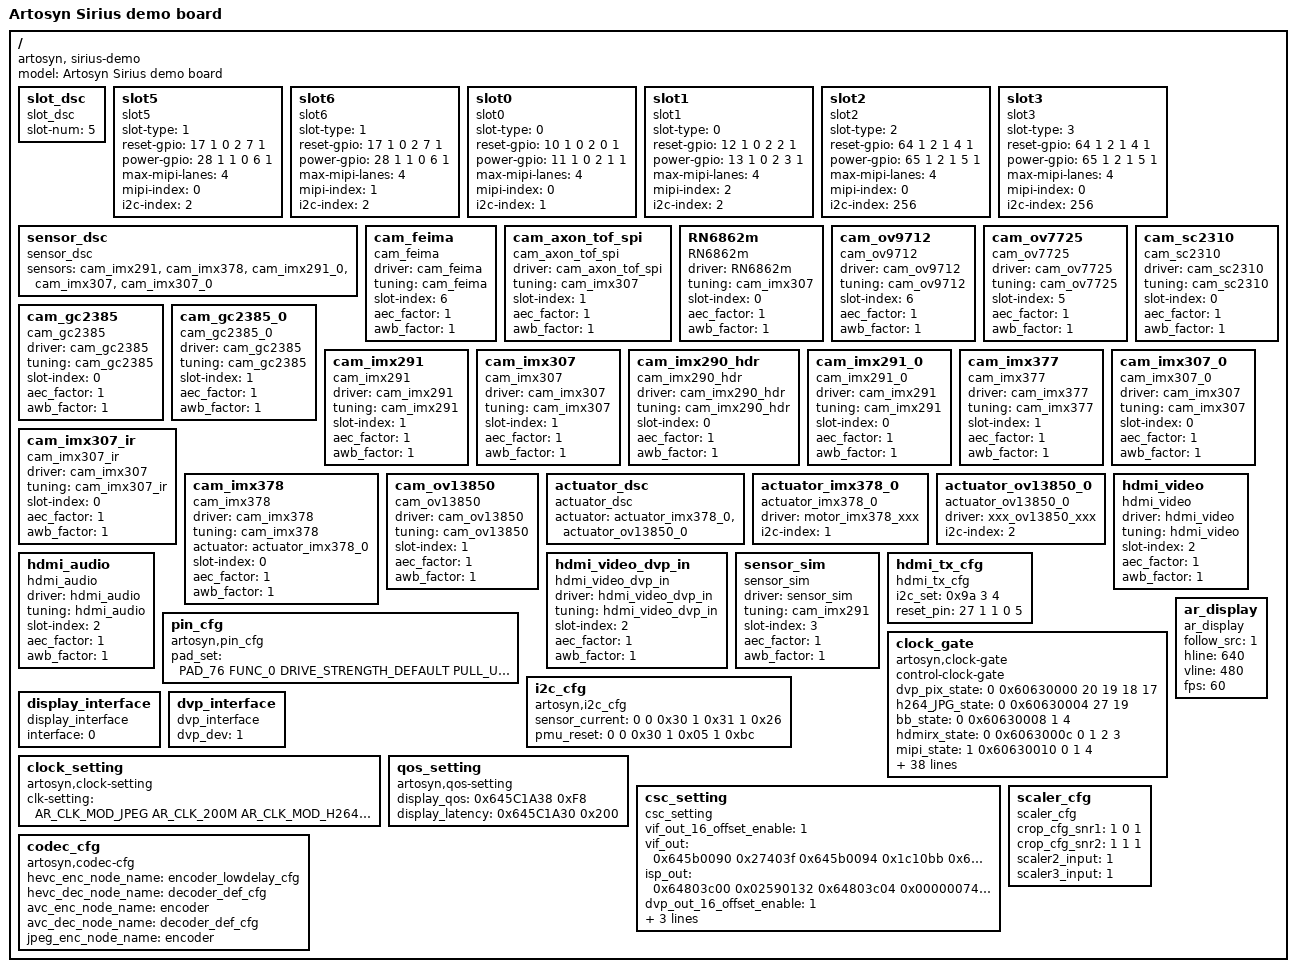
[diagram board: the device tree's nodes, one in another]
/*
 * Copyright 2015 Hans de Goede <hdegoede@redhat.com>
 *
 * Minimal dts file for the MSI Primo81 for u-boot only
 *
 * SPDX-License-Identifier:     GPL-2.0+ or X11
 */


/dts-v1/;
#include <ar_clk.h>
#include <ar_pads.h>

/{
	model = "Artosyn Sirius demo board";
	compatible = "artosyn, sirius-demo";

	slot_dsc{
		compatible = "slot_dsc";
		slot-num = <5>;
	};

	slot5 {
		compatible = "slot5";
		slot-type = <1>;
		//padnum, gpio_function_num ,group, port,num,in_out
		reset-gpio = <17 1 0 2 7 1>;
        //dvp power not config
		power-gpio = <28 1 1 0 6 1>;
		//mipi lane num
		max-mipi-lanes = <4>;
        //dvp_index
		mipi-index = <0>;
		//i2c index
		i2c-index = <2>;

	};

	slot6 {
		compatible = "slot6";
		slot-type = <1>;
		//padnum, gpio_function_num ,group, port,num,in_out
		reset-gpio = <17 1 0 2 7 1>;
        //dvp power not config
		power-gpio = <28 1 1 0 6 1>;
		//mipi lane num
		max-mipi-lanes = <4>;
        //dvp_index
		mipi-index = <1>;
		//i2c index
		i2c-index = <2>;

	};
	slot0 {
		compatible = "slot0";
		slot-type = <0>;
		//padnum, gpio_function_num ,group, port,num,in_out
		reset-gpio = <10 1 0 2 0 1>;
		power-gpio = <11 1 0 2 1 1>;
		//mipi lane num
		max-mipi-lanes = <4>;
		mipi-index = <0>;
		//i2c index
		i2c-index = <1>;

	};

	slot1 {
		compatible = "slot1";
		slot-type = <0>;
		//padnum, gpio_function_num ,group, port,num,in_out
		reset-gpio = <12 1 0 2 2 1>;
		power-gpio = <13 1 0 2 3 1>;
		//mipi lane num
		max-mipi-lanes = <4>;
		mipi-index = <2>;
		//i2c index
		i2c-index = <2>;

	};
	slot2 {
		compatible = "slot2";
		slot-type = <2>;
		//padnum, gpio_function_num ,group, port,num,in_out
		reset-gpio = <64 1 2 1 4 1>;
		power-gpio = <65 1 2 1 5 1>;
		//mipi lane num
		max-mipi-lanes = <4>;
		mipi-index = <0>;
		//i2c index
		i2c-index = <256>;

	};
	slot3 {
		compatible = "slot3";
		slot-type = <3>;
		//padnum, gpio_function_num ,group, port,num,in_out
		reset-gpio = <64 1 2 1 4 1>;
		power-gpio = <65 1 2 1 5 1>;
		//mipi lane num
		max-mipi-lanes = <4>;
		mipi-index = <0>;
		//i2c index
		i2c-index = <256>;

	};
	sensor_dsc{
		compatible = "sensor_dsc";
                //the sensor need to prob
		sensors ="cam_imx291" , "cam_imx378", "cam_imx291_0" , "cam_imx307" , "cam_imx307_0";
	};
        //comatible will decidecd which driver will used
        //node will give the driver to creat sensor obj which name is it, and this name will decided which tuning header will
        //be used
    cam_feima{
        compatible = "cam_feima";
        driver       = "cam_feima";
        tuning      = "cam_feima";
        slot-index = <6>;
        aec_factor = <1>;
        awb_factor = <1>;
    };
    cam_axon_tof_spi{
        compatible   = "cam_axon_tof_spi";
        driver       = "cam_axon_tof_spi";
        tuning       = "cam_imx307";
        slot-index   = <1>;
        aec_factor   = <1>;
        awb_factor   = <1>;
    };
    RN6862m{
        compatible = "RN6862m";
        driver       = "RN6862m";
        tuning      = "cam_imx307";
        slot-index = <0>;
        aec_factor = <1>;
        awb_factor = <1>;
    };
    cam_ov9712{
        compatible = "cam_ov9712";
        driver       = "cam_ov9712";
        tuning      = "cam_ov9712";
        slot-index = <6>;
        aec_factor = <1>;
        awb_factor = <1>;
    };
    cam_ov7725{
        compatible = "cam_ov7725";
        driver       = "cam_ov7725";
        tuning      = "cam_ov7725";
        slot-index = <5>;
        aec_factor = <1>;
        awb_factor = <1>;
    };
	cam_sc2310{
		compatible = "cam_sc2310";
                driver       = "cam_sc2310";
                tuning      = "cam_sc2310";
		slot-index = <0>;
		aec_factor = <1>;
		awb_factor = <1>;
	};
	cam_gc2385{
		compatible = "cam_gc2385";
                driver       = "cam_gc2385";
                tuning       = "cam_gc2385";
		slot-index = <0>;
		aec_factor = <1>;
		awb_factor = <1>;
	};

	cam_gc2385_0{
		compatible = "cam_gc2385_0";
                driver       = "cam_gc2385";
                tuning       = "cam_gc2385";
		slot-index = <1>;
		aec_factor = <1>;
		awb_factor = <1>;
	};
	cam_imx291{
		compatible = "cam_imx291";
                driver       = "cam_imx291";
                tuning       = "cam_imx291";
		slot-index = <1>;
		aec_factor = <1>;
		awb_factor = <1>;
	};
	cam_imx307{
		compatible = "cam_imx307";
                driver = "cam_imx307";
                tuning= "cam_imx307";
		slot-index = <1>;
		aec_factor = <1>;
		awb_factor = <1>;
	};
        cam_imx290_hdr{
		compatible = "cam_imx290_hdr";
                driver = "cam_imx290_hdr";
                tuning = "cam_imx290_hdr";
		slot-index = <0>;
		aec_factor = <1>;
		awb_factor = <1>;
	};
	cam_imx291_0{
		compatible = "cam_imx291_0";
                driver = "cam_imx291";
                tuning = "cam_imx291";
		slot-index = <0>;
		aec_factor = <1>;
		awb_factor = <1>;
		};
	cam_imx377{
		compatible = "cam_imx377";
                driver      = "cam_imx377";
                tuning     = "cam_imx377";
		slot-index = <1>;
		aec_factor = <1>;
		awb_factor = <1>;
	};

	cam_imx307_0{
		compatible = "cam_imx307_0";
                driver = "cam_imx307";
                tuning= "cam_imx307";
		slot-index = <0>;
		aec_factor = <1>;
		awb_factor = <1>;
	};

	cam_imx307_ir{
		compatible = "cam_imx307_ir";
                driver = "cam_imx307";
                tuning= "cam_imx307_ir";
		slot-index = <0>;
		aec_factor = <1>;
		awb_factor = <1>;
	};
    cam_imx378{
        compatible   = "cam_imx378";
        driver       = "cam_imx378";
        tuning       = "cam_imx378";
        actuator     = "actuator_imx378_0";
        slot-index   = <0>;
        aec_factor   = <1>;
        awb_factor   = <1>;
    };

	cam_ov13850{
		compatible = "cam_ov13850";
                driver     = "cam_ov13850";
                tuning     = "cam_ov13850";
		slot-index = <1>;
		aec_factor = <1>;
		awb_factor = <1>;
	};

    actuator_dsc{
        compatible = "actuator_dsc";
        //the actuator need to be created max 16
        actuator = "actuator_imx378_0" , "actuator_ov13850_0";
    };
    actuator_imx378_0{
        compatible = "actuator_imx378_0";
        driver = "motor_imx378_xxx";
        i2c-index = <1>;
    };
    actuator_ov13850_0{
        compatible = "actuator_ov13850_0";
        driver = "xxx_ov13850_xxx";
        i2c-index = <2>;
    };

	hdmi_video{
		compatible = "hdmi_video";
                driver       = "hdmi_video";
                tuning      = "hdmi_video";
		slot-index = <2>;
		aec_factor = <1>;
		awb_factor = <1>;
	};
	hdmi_audio{
		compatible = "hdmi_audio";
                driver       = "hdmi_audio";
                tuning     = "hdmi_audio";
		slot-index = <2>;
		aec_factor = <1>;
		awb_factor = <1>;
	};
	hdmi_video_dvp_in{
		compatible = "hdmi_video_dvp_in";
                driver       =  "hdmi_video_dvp_in";
                tuning    = "hdmi_video_dvp_in";
		slot-index = <2>;
		aec_factor = <1>;
		awb_factor = <1>;
	};
       sensor_sim{
		compatible = "sensor_sim";
                driver = "sensor_sim";
                tuning = "cam_imx291";
		slot-index = <3>;
		aec_factor = <1>;
		awb_factor = <1>;
	};

	hdmi_tx_cfg {
		compatible = "hdmi_tx_cfg";
		//<i2c_component subaddr>
		i2c_set = <0x9a 3 4>;
		//<pad function group port gpio>
		reset_pin = <27 1 1 0 5>;
	};

	pin_cfg {
                compatible = "artosyn,pin_cfg";
                pad_set  =    <
				//pin_share_qspi
				PAD_76	FUNC_0	DRIVE_STRENGTH_DEFAULT	PULL_UP_OR_DOWN_DEFAULT	VALUE_DEFAULT
				PAD_77	FUNC_0	DRIVE_STRENGTH_DEFAULT	PULL_UP_OR_DOWN_DEFAULT	VALUE_DEFAULT
				PAD_78	FUNC_0	DRIVE_STRENGTH_DEFAULT	PULL_UP_OR_DOWN_DEFAULT	VALUE_DEFAULT
				PAD_79	FUNC_0	DRIVE_STRENGTH_DEFAULT	PULL_UP_OR_DOWN_DEFAULT	VALUE_DEFAULT
				PAD_80	FUNC_0	DRIVE_STRENGTH_DEFAULT	PULL_UP_OR_DOWN_DEFAULT	VALUE_DEFAULT
				PAD_81	FUNC_0	DRIVE_STRENGTH_DEFAULT	PULL_UP_OR_DOWN_DEFAULT	VALUE_DEFAULT
				PAD_82	FUNC_0	DRIVE_STRENGTH_DEFAULT	PULL_UP_OR_DOWN_DEFAULT	VALUE_DEFAULT
				PAD_83	FUNC_0	DRIVE_STRENGTH_DEFAULT	PULL_UP_OR_DOWN_DEFAULT	VALUE_DEFAULT
				//pin_share_ethnet
				PAD_121	FUNC_0	DRIVE_STRENGTH_DEFAULT	PULL_UP_OR_DOWN_DEFAULT	VALUE_DEFAULT
				PAD_122	FUNC_0	DRIVE_STRENGTH_DEFAULT	PULL_UP_OR_DOWN_DEFAULT	VALUE_DEFAULT
				PAD_123	FUNC_0	DRIVE_STRENGTH_DEFAULT	PULL_UP_OR_DOWN_DEFAULT	VALUE_DEFAULT
				PAD_124	FUNC_0	DRIVE_STRENGTH_DEFAULT	PULL_UP_OR_DOWN_DEFAULT	VALUE_DEFAULT
				PAD_125	FUNC_0	DRIVE_STRENGTH_DEFAULT	PULL_UP_OR_DOWN_DEFAULT	VALUE_DEFAULT
				PAD_126	FUNC_0	DRIVE_STRENGTH_DEFAULT	PULL_UP_OR_DOWN_DEFAULT	VALUE_DEFAULT
				PAD_127	FUNC_0	DRIVE_STRENGTH_DEFAULT	PULL_UP_OR_DOWN_DEFAULT	VALUE_DEFAULT
				PAD_128	FUNC_0	DRIVE_STRENGTH_DEFAULT	PULL_UP_OR_DOWN_DEFAULT	VALUE_DEFAULT
				PAD_129	FUNC_0	DRIVE_STRENGTH_DEFAULT	PULL_UP_OR_DOWN_DEFAULT	VALUE_DEFAULT
				PAD_130	FUNC_0	DRIVE_STRENGTH_DEFAULT	PULL_UP_OR_DOWN_DEFAULT	VALUE_DEFAULT
				PAD_131	FUNC_0	DRIVE_STRENGTH_DEFAULT	PULL_UP_OR_DOWN_DEFAULT	VALUE_DEFAULT
				PAD_132	FUNC_0	DRIVE_STRENGTH_DEFAULT	PULL_UP_OR_DOWN_DEFAULT	VALUE_DEFAULT
				PAD_133	FUNC_0	DRIVE_STRENGTH_DEFAULT	PULL_UP_OR_DOWN_DEFAULT	VALUE_DEFAULT
				PAD_134	FUNC_0	DRIVE_STRENGTH_DEFAULT	PULL_UP_OR_DOWN_DEFAULT	VALUE_DEFAULT
				PAD_135	FUNC_0	DRIVE_STRENGTH_DEFAULT	PULL_UP_OR_DOWN_DEFAULT	VALUE_DEFAULT
				PAD_136	FUNC_0	DRIVE_STRENGTH_DEFAULT	PULL_UP_OR_DOWN_DEFAULT	VALUE_DEFAULT
				PAD_137	FUNC_0	DRIVE_STRENGTH_DEFAULT	PULL_UP_OR_DOWN_DEFAULT	VALUE_DEFAULT
				//pin_share_i2s_master1_for_sensor_clock
				PAD_64	FUNC_0	DRIVE_STRENGTH_DEFAULT	PULL_UP_OR_DOWN_DEFAULT	VALUE_DEFAULT
				PAD_65	FUNC_0	DRIVE_STRENGTH_DEFAULT	PULL_UP_OR_DOWN_DEFAULT	VALUE_DEFAULT
				PAD_66	FUNC_0	DRIVE_STRENGTH_DEFAULT	PULL_UP_OR_DOWN_DEFAULT	VALUE_DEFAULT
				PAD_67	FUNC_0	DRIVE_STRENGTH_DEFAULT	PULL_UP_OR_DOWN_DEFAULT	VALUE_DEFAULT
				//pin_share_bb_spi
				PAD_6	FUNC_4	DRIVE_STRENGTH_DEFAULT	PULL_UP_OR_DOWN_DEFAULT	VALUE_DEFAULT
				PAD_7	FUNC_4	DRIVE_STRENGTH_DEFAULT	PULL_UP_OR_DOWN_DEFAULT	VALUE_DEFAULT
				PAD_8	FUNC_4	DRIVE_STRENGTH_DEFAULT	PULL_UP_OR_DOWN_DEFAULT	VALUE_DEFAULT
				PAD_9	FUNC_4	DRIVE_STRENGTH_DEFAULT	PULL_UP_OR_DOWN_DEFAULT	VALUE_DEFAULT
				PAD_18	FUNC_2	DRIVE_STRENGTH_DEFAULT	PULL_UP_OR_DOWN_DEFAULT	VALUE_DEFAULT
				PAD_19	FUNC_2	DRIVE_STRENGTH_DEFAULT	PULL_UP_OR_DOWN_DEFAULT	VALUE_DEFAULT
				PAD_20	FUNC_2	DRIVE_STRENGTH_DEFAULT	PULL_UP_OR_DOWN_DEFAULT	VALUE_DEFAULT
				PAD_21	FUNC_2	DRIVE_STRENGTH_DEFAULT	PULL_UP_OR_DOWN_DEFAULT	VALUE_DEFAULT
				PAD_26	FUNC_0	DRIVE_STRENGTH_DEFAULT	PULL_UP_OR_DOWN_DEFAULT	VALUE_DEFAULT
				PAD_27	FUNC_1	DRIVE_STRENGTH_DEFAULT	PULL_UP_OR_DOWN_DEFAULT	VALUE_DEFAULT
				PAD_28	FUNC_0	DRIVE_STRENGTH_DEFAULT	PULL_UP_OR_DOWN_DEFAULT	VALUE_DEFAULT
				PAD_29	FUNC_0	DRIVE_STRENGTH_DEFAULT	PULL_UP_OR_DOWN_DEFAULT	VALUE_DEFAULT
				PAD_68	FUNC_4	DRIVE_STRENGTH_DEFAULT	PULL_UP_OR_DOWN_DEFAULT	VALUE_DEFAULT
				PAD_69	FUNC_4	DRIVE_STRENGTH_DEFAULT	PULL_UP_OR_DOWN_DEFAULT	VALUE_DEFAULT
				PAD_70	FUNC_4	DRIVE_STRENGTH_DEFAULT	PULL_UP_OR_DOWN_DEFAULT	VALUE_DEFAULT
				PAD_71	FUNC_4	DRIVE_STRENGTH_DEFAULT	PULL_UP_OR_DOWN_DEFAULT	VALUE_DEFAULT
				PAD_72	FUNC_4	DRIVE_STRENGTH_DEFAULT	PULL_UP_OR_DOWN_DEFAULT	VALUE_DEFAULT
				PAD_73	FUNC_4	DRIVE_STRENGTH_DEFAULT	PULL_UP_OR_DOWN_DEFAULT	VALUE_DEFAULT
				PAD_74	FUNC_4	DRIVE_STRENGTH_DEFAULT	PULL_UP_OR_DOWN_DEFAULT	VALUE_DEFAULT
				PAD_75	FUNC_4	DRIVE_STRENGTH_DEFAULT	PULL_UP_OR_DOWN_DEFAULT	VALUE_DEFAULT
				//pin_share_ceva_uart
				PAD_47	FUNC_3	DRIVE_STRENGTH_DEFAULT	PULL_UP_OR_DOWN_DEFAULT	VALUE_DEFAULT
				PAD_44	FUNC_0	DRIVE_STRENGTH_DEFAULT	PULL_UP_OR_DOWN_DEFAULT	VALUE_DEFAULT
				PAD_45	FUNC_0	DRIVE_STRENGTH_DEFAULT	PULL_UP_OR_DOWN_DEFAULT	VALUE_DEFAULT
				//pin_share_dvp_data
				PAD_100	FUNC_4	DRIVE_STRENGTH_DEFAULT	PULL_UP_OR_DOWN_DEFAULT	VALUE_DEFAULT
				PAD_101	FUNC_4	DRIVE_STRENGTH_DEFAULT	PULL_UP_OR_DOWN_DEFAULT	VALUE_DEFAULT
				PAD_102	FUNC_4	DRIVE_STRENGTH_DEFAULT	PULL_UP_OR_DOWN_DEFAULT	VALUE_DEFAULT
				PAD_103	FUNC_4	DRIVE_STRENGTH_DEFAULT	PULL_UP_OR_DOWN_DEFAULT	VALUE_DEFAULT
				PAD_104	FUNC_4	DRIVE_STRENGTH_DEFAULT	PULL_UP_OR_DOWN_DEFAULT	VALUE_DEFAULT
				PAD_105	FUNC_4	DRIVE_STRENGTH_DEFAULT	PULL_UP_OR_DOWN_DEFAULT	VALUE_DEFAULT
				PAD_106	FUNC_4	DRIVE_STRENGTH_DEFAULT	PULL_UP_OR_DOWN_DEFAULT	VALUE_DEFAULT
				PAD_107	FUNC_4	DRIVE_STRENGTH_DEFAULT	PULL_UP_OR_DOWN_DEFAULT	VALUE_DEFAULT
				PAD_17	FUNC_1	DRIVE_STRENGTH_DEFAULT	PULL_UP_OR_DOWN_DEFAULT	VALUE_DEFAULT
				//pin_share_system_rest
				PAD_46	FUNC_1	DRIVE_STRENGTH_DEFAULT	PULL_UP_OR_DOWN_DEFAULT	VALUE_DEFAULT
				//pin_share_da9062
				PAD_2	FUNC_4	DRIVE_STRENGTH_DEFAULT	PULL_UP_OR_DOWN_DEFAULT	VALUE_DEFAULT
				//pin_share_usb_oc
				PAD_119	FUNC_0	DRIVE_STRENGTH_1	PULL_UP_OR_DOWN_3	VALUE_DEFAULT>;
	};

	clock_gate {
		compatible = "artosyn,clock-gate";
		control-clock-gate;

		dvp_pix_state  = <0 0x60630000 20 19 18 17>;
		h264_JPG_state = <0 0x60630004 27 19>;
		bb_state     = <0 0x60630008 1 4>;
		hdmirx_state = <0 0x6063000c 0 1 2 3>;
		mipi_state   = <1 0x60630010 0 1 4>;
		usbc_state   = <0 0x60630014 0 1 2 3 4 5 6 7 8>;
		usb30_state  = <1 0x60630018 0 1>;
		pcie_state   = <0 0x6063001c 0 1>;
		m7_state     = <0 0x60630020 8 9 11>;
		//sec_clk_state = <0 0x60630024 0 1>;
		gmac_state   = <0 0x60630030 0 1 3>;
		emmc_state   = <0 0x60630034 0 1 2>;
		dvprx_state  = <0 0x6063003c 0 1>;
		sram_state   = <1 0x60630040 0>;
		codec_state  = <1 0x60630004 0 1 2 3 8 9 10 19 27>;

		sram_share_1 = <1 0x60634010 0>;	//sram share for ceva
		sram_share_0 = <0 0x60634010 17>;	//sram share for ceva

		SAR10_1_2_state = <1 0x60680380 0 1>;
		QDAC_IDAC_state = <1 0x60680384 21 22>;
                QDAC_IDAC2_state = <1 0x60680388 13 14>;
                adc_dac_state   = <1 0x6068038c 0 1 2 3 4 5 30 31>;
		ADCI_ADCQ_state  = <1 0x60680390 22 23>;
		ADCI_ADCQ2_state = <1 0x60680394 14 15>;
		ADCI_ADCQ3_state = <1 0x60680398 6 7>;
		SAR10_3_state   = <1 0x60632018 0>;
		sdc_pll_state   = <1 0x606320fc 0>;

		isp_mem_sd_state = <1 0x64800090 6>;
		m7_mem_sd_state = <1 0x40B0000C 7>;
		bootrom_mem_sd_state = <1 0x60634004 2>;
		H265_mem_sd_state = <1 0x6063400c 26>;
		H264_mem_sd_state = <1 0x60634010 16 17>;
		jpg_mem_sd_state = <1 0x60634014 1>;
		disp_mem_sd_state = <1 0x60634018 2>;
		smmu_mem_sd_state = <1 0x6063401c 0 6>;
		emmc_mem_sd_state = <1 0x64501000 2>;
		usbc_mem_sd_state = <1 0x603C000C 1 3 5 7 9 11 13 15 17 19 21 23 25 27 29 31>;

		pcie_phy_state = <1 0x64280240 1>;
		//usb3_phy_state = <1 0x60609034 2>;
		M7_core_reset_state = <0 0x60631020 0>;
		hdmi_phy_state = <1 0x645e02c0 0 1>;

		m7_throttle_state = <0 0x60630044 0 1 2 3 4 5 6 7 8 9 10 11 12 13 14 15 16 17 18 19 20 21 22 23 24 25 26 27 28 29 30 31>;
		m7_throttle2_state = <0 0x60630020 17>;
		m7_throttle3_state = <1 0x60630020 16 17>;
		//m7_ips_state = <0 0x40b00000 >;
		//m7_ips2_state = <0 0x40b00004 >;
	};

	ar_display{
		compatible = "ar_display";
		follow_src = <1>;
		hline = <640>;
		vline = <480>;
		fps   = <60>;
	};

	i2c_cfg {
		compatible = "artosyn,i2c_cfg";
		//<i2c-num  read-write chip_addr addr_len register_addr byte_len byte ....>
		sensor_current = <0 0 0x30 1 0x31 1 0x26>;
		pmu_reset	   = <0 0 0x30 1 0x05 1 0xbc>;
	};

        display_interface{
		compatible = "display_interface";
                //dvp:0 dp:1 mipi:2
		interface  = <0>;
	};


	dvp_interface{
		compatible = "dvp_interface";
                //vga:0 hdmi:1 hx8264:2
		dvp_dev  = <1>;
	};

	clock_setting {
		compatible = "artosyn,clock-setting";
		clk-setting = <
			AR_CLK_MOD_JPEG			AR_CLK_200M
			AR_CLK_MOD_H264			AR_CLK_333M
			AR_CLK_MOD_ISP			AR_CLK_PIXEL
			AR_CLK_MOD_HEVC_CORE	        AR_CLK_300M
			AR_CLK_MOD_HEVC_BPU		AR_CLK_300M
			AR_CLK_MOD_VIF			AR_CLK_500M
			AR_CLK_MOD_AU_PLL_FOR_SENSOR	AR_CLK_AU_PLL_FOR_SENSOR
		>;
	};

	qos_setting {
		compatible = "artosyn,qos-setting";
		display_qos = <0x645C1A38 0xF8>;
		display_latency = <0x645C1A30 0x200>;
	};

       csc_setting{
               compatible = "csc_setting";
               vif_out_16_offset_enable = <1>;
               vif_out=<
                       0x645b0090 0x27403f
                       0x645b0094 0x1c10bb
                       0x645b0098 0xf99ea5
                       0x645b009C 0xe68fd8
                       0x645b00A0 0x0001c1
                       0x645b00A8 0xc0eb0eb0
                >;
                isp_out=<
                       0x64803c00 0x02590132
                       0x64803c04 0x00000074
                       0x64803c08 0x815380ae
                       0x64803c0c 0x02000200
                       0x64803c10 0x81ae0200
	                   0x64803c14 0x02008053
                       0x64803c00 0x02590132
                       0x64803c04 0x00000074
                       0x64803c08 0x815380ae
                       0x64803c0c 0x02000200
                       0x64803c10 0x81ae0200
	                   0x64803c14 0x02008053
                >;
                dvp_out_16_offset_enable = <1>;
                dvp_out=<
                       0x645b0160 0x2750bb
                       0x645b0164 0x1c203f
                       0x645b0168 0xfd7e67
                       0x645b016c 0xea6f99
                       0x645b0170 0x0001c2
                       0x645b00ac 0x90f0eb
                >;
                //<enable itu709/601 limit/full>
		//itu709/601 value==1 ->VIDMODE_ITU709
		//itu709/601 value==0 ->VIDMODE_ITU601
		//limit/full value==1 ->VIDMODE_16_235
		//limit/full value==0 ->VIDMODE_0_255
                hdmi_tx_colormodeset = <1 1 1>;
       };
       scaler_cfg{
             compatible = "scaler_cfg";
             //scaler1 2 3
             crop_cfg_snr1=<1 0 1 >;
             crop_cfg_snr2=<1 1 1 >;
             //scaler2 input sel, 0, frome cnf in, 1 frome crop 1 in
             scaler2_input = <1>;
             //scaler2 input sel, 0, frome cnf in, 1 frome crop 1 in
             scaler3_input = <1>;
       };
       codec_cfg {
           compatible = "artosyn,codec-cfg";
           hevc_enc_node_name = "encoder_lowdelay_cfg";
           hevc_dec_node_name = "decoder_def_cfg";
           avc_enc_node_name = "encoder";
           avc_dec_node_name = "decoder_def_cfg";
           jpeg_enc_node_name = "encoder";
       };
};
